VERSION "manually crafted"

NS_ :

BS_:

BU_:

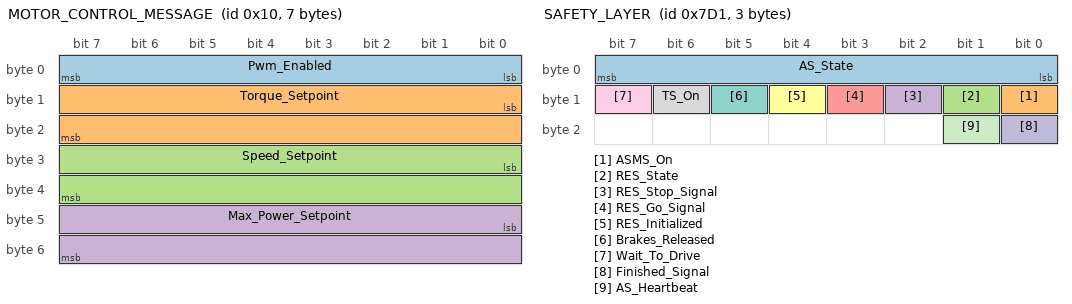
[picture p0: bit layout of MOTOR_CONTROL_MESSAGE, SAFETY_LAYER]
BO_ 16 MOTOR_CONTROL_MESSAGE: 7 Vector__XXX
 SG_ Pwm_Enabled : 0|8@1+ (1,0) [0|0] "" Vector__XXX
 SG_ Torque_Setpoint : 8|16@1+ (1,0) [0|0] "" Vector__XXX
 SG_ Speed_Setpoint : 24|16@1+ (1,0) [0|0] "" Vector__XXX
 SG_ Max_Power_Setpoint : 40|16@1+ (1,0) [0|0] "" Vector__XXX

BO_ 31 FRONT_NODE_STATUS: 2 Vector__XXX
 SG_ Counter : 0|8@1- (1,0) [0|0] "" Vector__XXX
 SG_ Ready_To_Drive : 8|8@1- (1,0) [0|0] "" Vector__XXX

BO_ 32 REAR_NODE_STATUS: 2 Vector__XXX
 SG_ Counter : 0|8@1- (1,0) [0|0] "" Vector__XXX
 SG_ Ready_To_Drive : 8|8@1- (1,0) [0|0] "" Vector__XXX

BO_ 33 AUTONOMOUS_NODE_STATUS: 2 Vector__XXX
 SG_ Counter : 0|8@1- (1,0) [0|0] "" Vector__XXX
 SG_ Ready_To_Drive : 8|8@1- (1,0) [0|0] "" Vector__XXX

BO_ 34 AMS_STATUS: 2 Vector__XXX
 SG_ Counter : 0|8@1- (1,0) [0|0] "" Vector__XXX
 SG_ Ready_To_Drive : 8|8@1- (1,0) [0|0] "" Vector__XXX

BO_ 501 APPS_1: 4 Vector__XXX
 SG_ Throttle_Percentage : 0|32@1+ (1,0) [0.0|100.0] "per" Vector__XXX

BO_ 502 APPS_2: 4 Vector__XXX
 SG_ Throttle_Percentage : 0|32@1+ (1,0) [0.0|100.0] "per" Vector__XXX

BO_ 503 HYDRAULIC_BRAKE_PRESSURE_1: 4 Vector__XXX
 SG_ Hydraulic_Pressure : 0|32@1+ (1,0) [0.0|100.0] "per" Vector__XXX

BO_ 504 HYDRAULIC_BRAKE_PRESSURE_2: 4 Vector__XXX
 SG_ Hydraulic_Pressure : 0|32@1+ (1,0) [0.0|100.0] "per" Vector__XXX

BO_ 505 BRAKE_DISK_TEMP_1: 4 Vector__XXX
 SG_ Brake_Disk_Temp : 0|32@1+ (1,0) [0.0|100.0] "per" Vector__XXX

BO_ 506 BRAKE_DISK_TEMP_2: 4 Vector__XXX
 SG_ Brake_Disk_Temp : 0|32@1+ (1,0) [0.0|100.0] "per" Vector__XXX

BO_ 507 DAMPER_POSITION_1: 4 Vector__XXX
 SG_ Damper_Position : 0|32@1+ (1,0) [0.0|100.0] "per" Vector__XXX

BO_ 508 DAMPER_POSITION_2: 4 Vector__XXX
 SG_ Damper_Position : 0|32@1+ (1,0) [0.0|100.0] "per" Vector__XXX

BO_ 509 PNUEMATIC_PRESSURE_1: 4 Vector__XXX
 SG_ Pnuematic_Pressure : 0|32@1+ (1,0) [0.0|100.0] "per" Vector__XXX

BO_ 510 PNUEMATIC_PRESSURE_2: 4 Vector__XXX
 SG_ Pnuematic_Pressure : 0|32@1+ (1,0) [0.0|100.0] "per" Vector__XXX

BO_ 511 PNUEMATIC_PRESSURE_3: 4 Vector__XXX
 SG_ Pnuematic_Pressure : 0|32@1+ (1,0) [0.0|100.0] "per" Vector__XXX

BO_ 512 STEERING_POSITION_1: 4 Vector__XXX
 SG_ Steering_Position : 0|32@1+ (1,0) [0.0|100.0] "per" Vector__XXX

BO_ 513 STEERING_POSITION_2: 4 Vector__XXX
 SG_ Steering_Position : 0|32@1+ (1,0) [0.0|100.0] "per" Vector__XXX

BO_ 200 TEST_CAN_MESSAGE_1: 1 Vector__XXX
 SG_ Test_Message : 0|8@1+ (1,0) [0|0] "" Vector__XXX

BO_ 201 TEST_CAN_MESSAGE_2: 1 Vector__XXX
 SG_ Test_Message : 0|8@1+ (1,0) [0|0] "" Vector__XXX

BO_ 202 TEST_CAN_MESSAGE_3: 1 Vector__XXX
 SG_ Test_Message : 0|8@1+ (1,0) [0|0] "" Vector__XXX

BO_ 2001 SAFETY_LAYER: 3 Vector__XXX
 SG_ AS_State : 0|8@1+ (1,0) [0|0] "" Vector__XXX
 SG_ ASMS_On : 8|1@1+ (1,0) [0|1] "" Vector__XXX
 SG_ RES_State : 9|1@1+ (1,0) [0|1] "" Vector__XXX
 SG_ RES_Stop_Signal : 10|1@1+ (1,0) [0|1] "" Vector__XXX
 SG_ RES_Go_Signal : 11|1@1+ (1,0) [0|1] "" Vector__XXX
 SG_ RES_Initialized : 12|1@1+ (1,0) [0|1] "" Vector__XXX
 SG_ Brakes_Released : 13|1@1+ (1,0) [0|0] "" Vector__XXX
 SG_ TS_On : 14|1@1+ (1,0) [0|0] "" Vector__XXX
 SG_ Wait_To_Drive : 15|1@1+ (1,0) [0|0] "" Vector__XXX
 SG_ Finished_Signal : 16|1@1+ (1,0) [0|0] "" Vector__XXX
 SG_ AS_Heartbeat : 17|1@1+ (1,0) [0|0] "" Vector__XXX

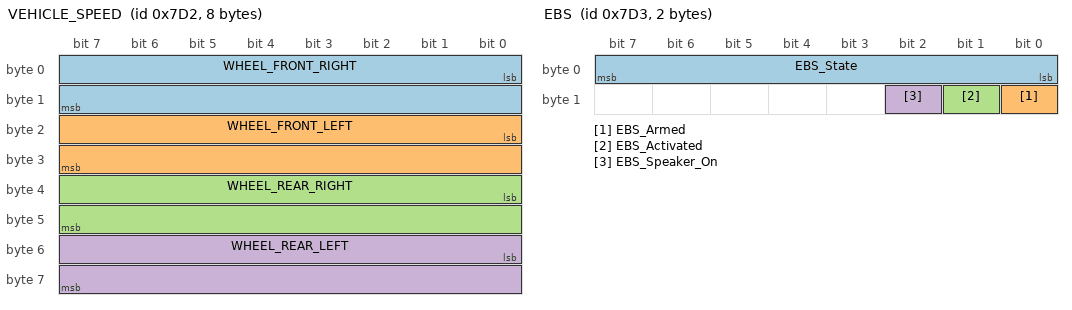
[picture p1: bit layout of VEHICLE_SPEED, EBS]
BO_ 2002 VEHICLE_SPEED: 8 Vector__XXX
 SG_ WHEEL_FRONT_RIGHT : 0|16@1+ (1,0) [0|0] "" Vector__XXX
 SG_ WHEEL_FRONT_LEFT : 16|16@1+ (1,0) [0|0] "" Vector__XXX
 SG_ WHEEL_REAR_RIGHT : 32|16@1+ (1,0) [0|0] "" Vector__XXX
 SG_ WHEEL_REAR_LEFT : 48|16@1+ (1,0) [0|0] "" Vector__XXX

BO_ 2003 EBS: 2 Vector__XXX
 SG_ EBS_State : 0|8@1+ (1,0) [0|0] "" Vector__XXX
 SG_ EBS_Armed : 8|1@1+ (1,0) [0|0] "" Vector__XXX
 SG_ EBS_Activated : 9|1@1+ (1,0) [0|0] "" Vector__XXX
 SG_ EBS_Speaker_On : 10|1@1+ (1,0) [0|0] "" Vector__XXX

BO_ 2005 AS_MISSION: 1 Vector__XXX
 SG_ Mission_Select : 0|8@1+ (1,0) [0|0] "" Vector__XXX

SIG_VALTYPE_ 501 Throttle_Percentage : 1;
SIG_VALTYPE_ 502 Throttle_Percentage : 1;
SIG_VALTYPE_ 503 Hydraulic_Pressure : 1;
SIG_VALTYPE_ 504 Hydraulic_Pressure : 1;
SIG_VALTYPE_ 505 Brake_Disk_Temp : 1;
SIG_VALTYPE_ 506 Brake_Disk_Temp : 1;
SIG_VALTYPE_ 507 Damper_Position : 1;
SIG_VALTYPE_ 508 Damper_Position : 1;
SIG_VALTYPE_ 509 Pnuematic_Pressure : 1;
SIG_VALTYPE_ 510 Pnuematic_Pressure : 1;
SIG_VALTYPE_ 511 Pnuematic_Pressure : 1;
SIG_VALTYPE_ 512 Steering_Position : 1;
SIG_VALTYPE_ 513 Steering_Position : 1;
